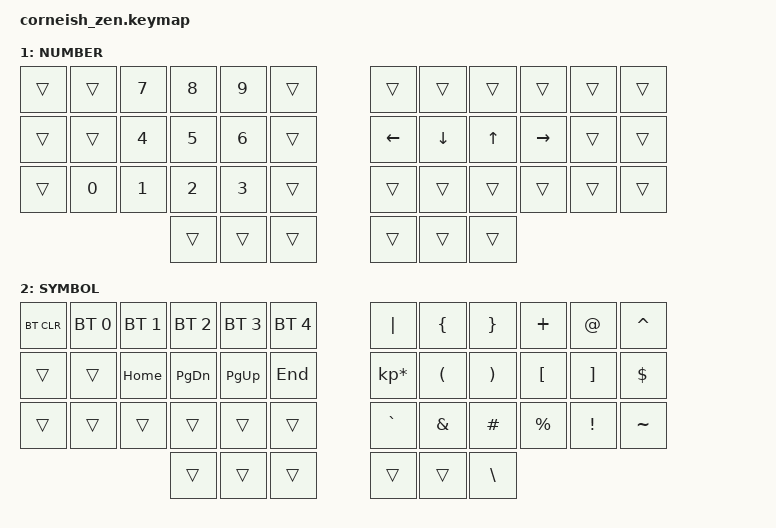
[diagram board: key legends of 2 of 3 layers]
#include <behaviors.dtsi>
#include <dt-bindings/zmk/keys.h>
#include <dt-bindings/zmk/bt.h>

/ {
  chosen {
    zmk,matrix_transform = &default_transform;
    //zmk,matrix_transform = &five_column_transform;
  };
};

/ {
        behaviors {
            hm: homerow_mods {
                compatible = "zmk,behavior-hold-tap";
                label = "HOMEROW_MODS";
                #binding-cells = <2>;
                tapping-term-ms = <300>;
                quick-tap-ms = <0>;
                flavor = "tap-preferred";
                bindings = <&kp>, <&kp>;
            };
        };

        keymap {
                compatible = "zmk,keymap";

                default_layer {
                        label = "QWERTY";
// ----------------------------------------   ----------------------------------------------
// |  TAB |  Q  |  W  |  E   |  R   |  T  |   |  Y  |  U   |  I  |  O  |  P  |  -        |
// |   =  |  A  |  S  |  D   |  F   |  G  |   |  H  |  J   |  K  |  L  |  ;  |  '        |
// |      |  Z  |  X  |  C   |  V   |  B  |   |  N  |  M   |  ,  |  .  |  /  | ESC/CTRL  |
//                    | BKSP | SHFT | RSE |   | ENT | SPC  | LSR |

                        bindings = <
   &kp TAB    &kp Q &kp W          &kp E         &kp R         &kp T                 &kp Y                  &kp U           &kp I           &kp O           &kp P    &kp MINUS
   &kp EQUAL  &kp A &hm LCTRL S    &hm LALT D    &hm LGUI F    &hm LA(LC(LSHFT)) G   &kp H                  &kp J           &kp K           &kp L           &kp SEMI &kp SQT
   &kp &trans &kp Z &kp X          &kp C         &kp V         &kp B                 &hm LA(LC(LSHFT)) N    &hm LGUI M      &hm LALT COMMA  &hm LCTRL DOT   &kp FSLH &kp ESC
                                   &kp BSPC      &kp LSHFT     &mo 2                 &kp RET                &kp SPACE       &mo 1
                        >;
                };
                lower_layer {
                        label = "NUMBER";
// --------------------------------------   ------------------------------------------------
// |      |     |  7  |  8  |  9  |     |   |     |     |     |     |     |      |
// |      |     |  4  |  5  |  6  |     |   | LFT | DWN |  UP | RGT |     |      |
// |      |  0  |  1  |  2  |  3  |     |   |     |     |     |     |     |      |
//                    |     |     |     |   |     |     |     |
                        bindings = <
   &trans &trans &kp N7 &kp N8 &kp N9 &trans      &trans   &trans   &trans &trans    &trans &trans
   &trans &trans &kp N4 &kp N5 &kp N6 &trans      &kp LEFT &kp DOWN &kp UP &kp RIGHT &trans &trans
   &trans &kp N0 &kp N1 &kp N2 &kp N3 &trans      &trans   &trans   &trans &trans    &trans &trans
                        &trans &trans &trans      &trans   &trans   &trans
                        >;
                };

                raise_layer {
                        label = "SYMBOL";
// ------------------------------------------   ------------------------------------------------
// | BTCL | BT1 | BT2 |  BT3  |  BT4  | BT5 |   | "|" |  {  |  }  |  +  |  @  |  ^  |
// |      |     |HOME | PG_DN | PG_UP | END |   |  *  |  (  |  )  |  [  |  ]  |  $  |
// |      |     |     |       |       |     |   |  `  |  &  |  #  |  %  |  !  |  ~  |
//                    |       |       |     |   |     |     |  \  |
                        bindings = <
   &bt BT_CLR   &bt BT_SEL 0 &bt BT_SEL 1 &bt BT_SEL 2 &bt BT_SEL 3  &bt BT_SEL 4    &kp PIPE        &kp LBRC &kp RBRC &kp PLUS  &kp AT    &kp CARET
   &trans       &trans       &kp HOME     &kp PG_DN    &kp PG_UP     &kp END         &kp KP_MULTIPLY &kp LPAR &kp RPAR &kp LBKT  &kp RBKT  &kp DLLR
   &trans       &trans       &trans       &trans       &trans        &trans          &kp GRAVE       &kp AMPS &kp HASH &kp PRCNT &kp EXCL  &kp TILDE
                                          &trans       &trans        &trans          &trans          &trans   &kp BSLH
                        >;
                };
        };
};
